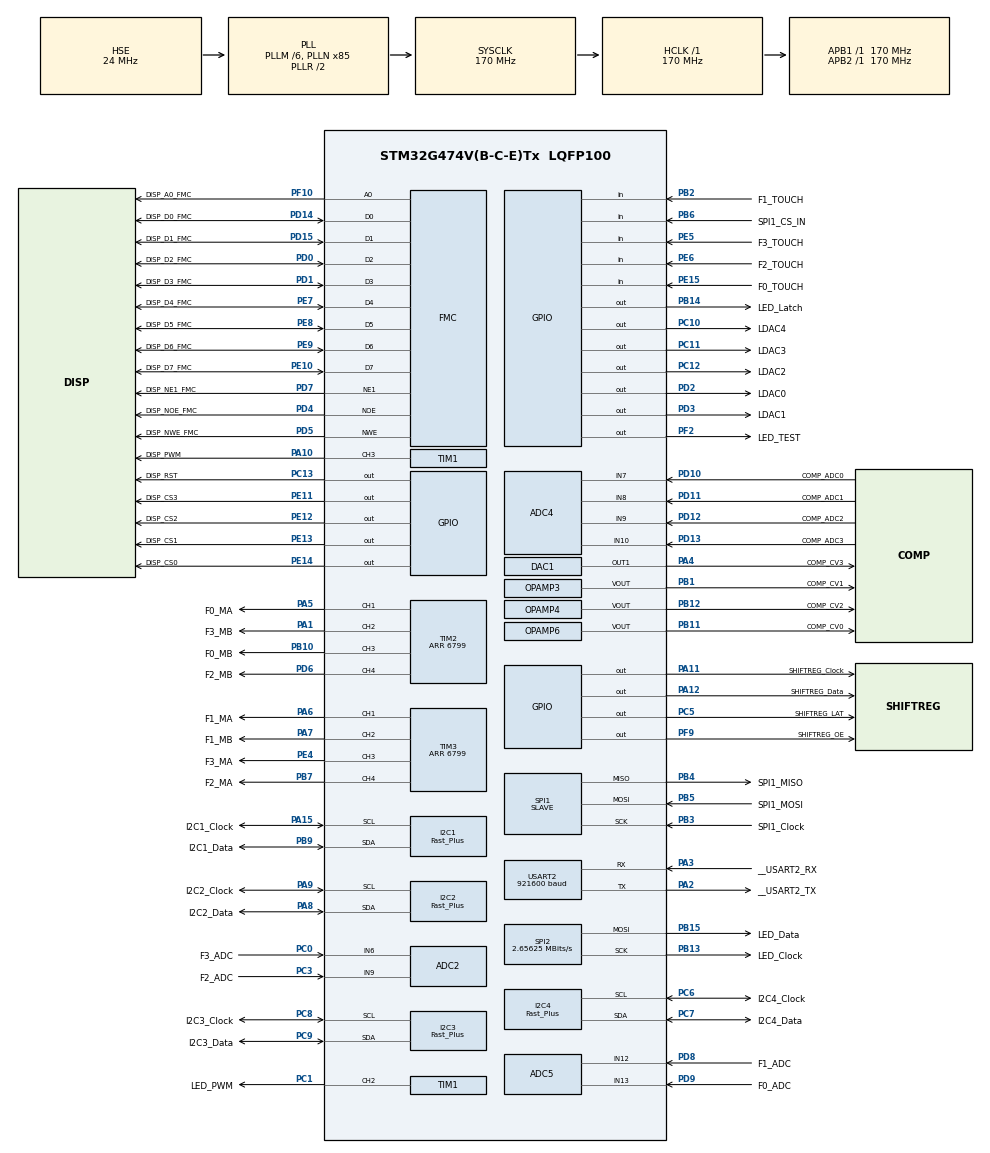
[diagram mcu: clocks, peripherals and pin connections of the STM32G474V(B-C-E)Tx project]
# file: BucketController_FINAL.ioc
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ADC2.Channel-1\#ChannelRegularConversion=ADC_CHANNEL_9
ADC2.Channel-2\#ChannelRegularConversion=ADC_CHANNEL_6
ADC2.ClockPrescaler=ADC_CLOCK_ASYNC_DIV256
ADC2.ContinuousConvMode=ENABLE
ADC2.DMAContinuousRequests=DISABLE
ADC2.NbrOfConversion=2
ADC2.NbrOfConversionFlag=1
ADC2.OffsetNumber-1\#ChannelRegularConversion=ADC_OFFSET_NONE
ADC2.OffsetNumber-2\#ChannelRegularConversion=ADC_OFFSET_NONE
ADC2.Rank-1\#ChannelRegularConversion=1
ADC2.Rank-2\#ChannelRegularConversion=2
ADC2.SamplingTime-1\#ChannelRegularConversion=ADC_SAMPLETIME_2CYCLES_5
ADC2.SamplingTime-2\#ChannelRegularConversion=ADC_SAMPLETIME_2CYCLES_5
ADC4.Channel-1\#ChannelRegularConversion=ADC_CHANNEL_7
ADC4.Channel-2\#ChannelRegularConversion=ADC_CHANNEL_8
ADC4.Channel-3\#ChannelRegularConversion=ADC_CHANNEL_9
ADC4.Channel-4\#ChannelRegularConversion=ADC_CHANNEL_10
ADC4.NbrOfConversion=4
ADC4.NbrOfConversionFlag=1
ADC4.OffsetNumber-1\#ChannelRegularConversion=ADC_OFFSET_NONE
ADC4.OffsetNumber-2\#ChannelRegularConversion=ADC_OFFSET_NONE
ADC4.OffsetNumber-3\#ChannelRegularConversion=ADC_OFFSET_NONE
ADC4.OffsetNumber-4\#ChannelRegularConversion=ADC_OFFSET_NONE
ADC4.Rank-1\#ChannelRegularConversion=1
ADC4.Rank-2\#ChannelRegularConversion=2
ADC4.Rank-3\#ChannelRegularConversion=3
ADC4.Rank-4\#ChannelRegularConversion=4
ADC4.SamplingTime-1\#ChannelRegularConversion=ADC_SAMPLETIME_2CYCLES_5
ADC4.SamplingTime-2\#ChannelRegularConversion=ADC_SAMPLETIME_2CYCLES_5
ADC4.SamplingTime-3\#ChannelRegularConversion=ADC_SAMPLETIME_2CYCLES_5
ADC4.SamplingTime-4\#ChannelRegularConversion=ADC_SAMPLETIME_2CYCLES_5
ADC5.Channel-1\#ChannelRegularConversion=ADC_CHANNEL_13
ADC5.Channel-2\#ChannelRegularConversion=ADC_CHANNEL_12
ADC5.NbrOfConversion=2
ADC5.NbrOfConversionFlag=1
ADC5.OffsetNumber-1\#ChannelRegularConversion=ADC_OFFSET_NONE
ADC5.OffsetNumber-2\#ChannelRegularConversion=ADC_OFFSET_NONE
ADC5.Rank-1\#ChannelRegularConversion=1
ADC5.Rank-2\#ChannelRegularConversion=2
ADC5.SamplingTime-1\#ChannelRegularConversion=ADC_SAMPLETIME_2CYCLES_5
ADC5.SamplingTime-2\#ChannelRegularConversion=ADC_SAMPLETIME_2CYCLES_5
DAC3.DAC_Channel-DAC_OUT2_Int=DAC_CHANNEL_2
Dma.Request0=SPI2_TX
Dma.SPI2_TX.0.Direction=DMA_MEMORY_TO_PERIPH
Dma.SPI2_TX.0.EventEnable=DISABLE
Dma.SPI2_TX.0.Instance=DMA1_Channel1
Dma.SPI2_TX.0.MemDataAlignment=DMA_MDATAALIGN_BYTE
Dma.SPI2_TX.0.MemInc=DMA_MINC_ENABLE
Dma.SPI2_TX.0.Mode=DMA_NORMAL
Dma.SPI2_TX.0.PeriphDataAlignment=DMA_PDATAALIGN_BYTE
Dma.SPI2_TX.0.PeriphInc=DMA_PINC_DISABLE
Dma.SPI2_TX.0.Polarity=HAL_DMAMUX_REQ_GEN_RISING
Dma.SPI2_TX.0.Priority=DMA_PRIORITY_LOW
Dma.SPI2_TX.0.RequestNumber=1
Dma.SPI2_TX.0.SignalID=NONE
Dma.SPI2_TX.0.SyncEnable=DISABLE
Dma.SPI2_TX.0.SyncPolarity=HAL_DMAMUX_SYNC_NO_EVENT
Dma.SPI2_TX.0.SyncRequestNumber=1
Dma.SPI2_TX.0.SyncSignalID=NONE
FMC.AddressSetupTime1=1
FMC.BusTurnAroundDuration1=0
FMC.DataHoldTime1=1
FMC.DataSetupTime1=4
FMC.WriteFifo1=FMC_WRITE_FIFO_DISABLE
FREERTOS.Tasks01=defaultTask,24,128,StartDefaultTask,Default,NULL,Dynamic,NULL,NULL
I2C1.I2C_Speed_Mode=I2C_Fast_Plus
I2C1.Speed=1000
I2C1.Timing=0x4052060F
I2C2.I2C_Speed_Mode=I2C_Fast_Plus
I2C2.Timing=0x4052060F
I2C3.I2C_Speed_Mode=I2C_Fast_Plus
I2C3.Timing=0x4052060F
I2C4.I2C_Speed_Mode=I2C_Fast_Plus
I2C4.Timing=0x4052060F
Mcu.Family=STM32G4
Mcu.Name=STM32G474V(B-C-E)Tx
Mcu.Package=LQFP100
NVIC.DMA1_Channel1_IRQn=true\:5\:0\:false\:false\:true\:true\:false\:true\:true
NVIC.PriorityGroup=NVIC_PRIORITYGROUP_4
NVIC.SPI2_IRQn=true\:5\:0\:false\:false\:true\:true\:true\:true\:true
NVIC.TIM4_IRQn=true\:5\:0\:false\:false\:true\:true\:true\:true\:true
NVIC.TIM5_IRQn=true\:5\:0\:false\:false\:true\:true\:true\:true\:true
NVIC.TIM7_DAC_IRQn=true\:5\:0\:false\:false\:true\:false\:false\:true\:true
NVIC.TimeBase=TIM7_DAC_IRQn
NVIC.TimeBaseIP=TIM7
PA1.GPIO_Label=F3_MB
PA1.GPIO_Speed=GPIO_SPEED_FREQ_HIGH
PA1.Signal=S_TIM2_CH2
PA10.GPIO_Label=DISP_PWM
PA10.Signal=S_TIM1_CH3
PA11.GPIO_Label=SHIFTREG_Clock
PA11.Signal=GPIO_Output
PA12.GPIO_Label=SHIFTREG_Data
PA12.Signal=GPIO_Output
PA13.GPIO_Label=__SWDIO
PA13.Mode=Serial_Wire
PA13.Signal=SYS_JTMS-SWDIO
PA14.GPIO_Label=__SWCLK
PA14.Mode=Serial_Wire
PA14.Signal=SYS_JTCK-SWCLK
PA15.GPIO_Label=I2C1_Clock
PA15.Mode=I2C
PA15.Signal=I2C1_SCL
PA2.GPIO_Label=__USART2_TX
PA2.Mode=Asynchronous
PA2.Signal=USART2_TX
PA3.GPIO_Label=__USART2_RX
PA3.Mode=Asynchronous
PA3.Signal=USART2_RX
PA4.GPIO_Label=COMP_CV3
PA4.Signal=COMP_DAC11_group
PA5.GPIO_Label=F0_MA
PA5.GPIO_Speed=GPIO_SPEED_FREQ_HIGH
PA5.Signal=S_TIM2_CH1
PA6.GPIO_Label=F1_MA
PA6.GPIO_Speed=GPIO_SPEED_FREQ_HIGH
PA6.Signal=S_TIM3_CH1
PA7.GPIO_Label=F1_MB
PA7.GPIO_Speed=GPIO_SPEED_FREQ_HIGH
PA7.Signal=S_TIM3_CH2
PA8.GPIO_Label=I2C2_Data
PA8.Mode=I2C
PA8.Signal=I2C2_SDA
PA9.GPIO_Label=I2C2_Clock
PA9.Mode=I2C
PA9.Signal=I2C2_SCL
PB1.GPIO_Label=COMP_CV1
PB1.Mode=Follower-DAC_OUT2-INP
PB1.Signal=OPAMP3_VOUT
PB10.GPIO_Label=F0_MB
PB10.GPIO_Speed=GPIO_SPEED_FREQ_HIGH
PB10.Signal=S_TIM2_CH3
PB11.GPIO_Label=COMP_CV0
PB11.Mode=Follower-DAC_OUT2-INP
PB11.Signal=OPAMP6_VOUT
PB12.GPIO_Label=COMP_CV2
PB12.Mode=Follower-DAC_OUT2-INP
PB12.Signal=OPAMP4_VOUT
PB13.GPIO_Label=LED_Clock
PB13.GPIO_Speed=GPIO_SPEED_FREQ_LOW
PB13.Mode=TX_Only_Simplex_Unidirect_Master
PB13.Signal=SPI2_SCK
PB14.GPIO_Label=LED_Latch
PB14.Signal=GPIO_Output
PB15.GPIO_Label=LED_Data
PB15.GPIO_Speed=GPIO_SPEED_FREQ_LOW
PB15.Mode=TX_Only_Simplex_Unidirect_Master
PB15.Signal=SPI2_MOSI
PB2.GPIO_Label=F1_TOUCH
PB2.Signal=GPIO_Input
PB3.GPIO_Label=SPI1_Clock
PB3.Mode=Full_Duplex_Slave
PB3.Signal=SPI1_SCK
PB4.GPIO_Label=SPI1_MISO
PB4.Mode=Full_Duplex_Slave
PB4.Signal=SPI1_MISO
PB5.GPIO_Label=SPI1_MOSI
PB5.Mode=Full_Duplex_Slave
PB5.Signal=SPI1_MOSI
PB6.GPIO_Label=SPI1_CS_IN
PB6.Signal=GPIO_Input
PB7.GPIO_Label=F2_MA
PB7.GPIO_Speed=GPIO_SPEED_FREQ_HIGH
PB7.Signal=S_TIM3_CH4
PB9.GPIO_Label=I2C1_Data
PB9.Mode=I2C
PB9.Signal=I2C1_SDA
PC0.GPIO_Label=F3_ADC
PC0.Mode=IN6-Single-Ended
PC0.Signal=ADC2_IN6
PC1.GPIO_Label=LED_PWM
PC1.Signal=S_TIM1_CH2
PC10.GPIO_Label=LDAC4
PC10.Signal=GPIO_Output
PC11.GPIO_Label=LDAC3
PC11.Signal=GPIO_Output
PC12.GPIO_Label=LDAC2
PC12.Signal=GPIO_Output
PC13.GPIO_Label=DISP_RST
PC13.Signal=GPIO_Output
PC3.GPIO_Label=F2_ADC
PC3.Mode=IN9-Single-Ended
PC3.Signal=ADC2_IN9
PC5.GPIO_Label=SHIFTREG_LAT
PC5.Signal=GPIO_Output
PC6.GPIO_Label=I2C4_Clock
PC6.Mode=I2C
PC6.Signal=I2C4_SCL
PC7.GPIO_Label=I2C4_Data
PC7.Mode=I2C
PC7.Signal=I2C4_SDA
PC8.GPIO_Label=I2C3_Clock
PC8.Mode=I2C
PC8.Signal=I2C3_SCL
PC9.GPIO_Label=I2C3_Data
PC9.Mode=I2C
PC9.Signal=I2C3_SDA
PD0.GPIO_Label=DISP_D2_FMC
PD0.Mode=8b-d1
PD0.Signal=FMC_D2
PD1.GPIO_Label=DISP_D3_FMC
PD1.Mode=8b-d1
PD1.Signal=FMC_D3
PD10.GPIO_Label=COMP_ADC0
PD10.Mode=IN7-Single-Ended
PD10.Signal=ADC4_IN7
PD11.GPIO_Label=COMP_ADC1
PD11.Mode=IN8-Single-Ended
PD11.Signal=ADC4_IN8
PD12.GPIO_Label=COMP_ADC2
PD12.Mode=IN9-Single-Ended
PD12.Signal=ADC4_IN9
PD13.GPIO_Label=COMP_ADC3
PD13.Mode=IN10-Single-Ended
PD13.Signal=ADC4_IN10
PD14.GPIO_Label=DISP_D0_FMC
PD14.Mode=8b-d1
PD14.Signal=FMC_D0
PD15.GPIO_Label=DISP_D1_FMC
PD15.Mode=8b-d1
PD15.Signal=FMC_D1
PD2.GPIO_Label=LDAC0
PD2.Signal=GPIO_Output
PD3.GPIO_Label=LDAC1
PD3.Signal=GPIO_Output
PD4.GPIO_Label=DISP_NOE_FMC
PD4.Mode=Lcd1
PD4.Signal=FMC_NOE
PD5.GPIO_Label=DISP_NWE_FMC
PD5.Mode=Lcd1
PD5.Signal=FMC_NWE
PD6.GPIO_Label=F2_MB
PD6.GPIO_Speed=GPIO_SPEED_FREQ_HIGH
PD6.Signal=S_TIM2_CH4
PD7.GPIO_Label=DISP_NE1_FMC
PD7.Mode=NorPsramChipSelect1_1
PD7.Signal=FMC_NE1
PD8.GPIO_Label=F1_ADC
PD8.Mode=IN12-Single-Ended
PD8.Signal=ADC5_IN12
PD9.GPIO_Label=F0_ADC
PD9.Mode=IN13-Single-Ended
PD9.Signal=ADC5_IN13
PE10.GPIO_Label=DISP_D7_FMC
PE10.Mode=8b-d1
PE10.Signal=FMC_D7
PE11.GPIO_Label=DISP_CS3
PE11.Signal=GPIO_Output
PE12.GPIO_Label=DISP_CS2
PE12.Signal=GPIO_Output
PE13.GPIO_Label=DISP_CS1
PE13.Signal=GPIO_Output
PE14.GPIO_Label=DISP_CS0
PE14.Signal=GPIO_Output
PE15.GPIO_Label=F0_TOUCH
PE15.Signal=GPIO_Input
PE4.GPIO_Label=F3_MA
PE4.GPIO_Speed=GPIO_SPEED_FREQ_HIGH
PE4.Signal=S_TIM3_CH3
PE5.GPIO_Label=F3_TOUCH
PE5.Signal=GPIO_Input
PE6.GPIO_Label=F2_TOUCH
PE6.Signal=GPIO_Input
PE7.GPIO_Label=DISP_D4_FMC
PE7.Mode=8b-d1
PE7.Signal=FMC_D4
PE8.GPIO_Label=DISP_D5_FMC
PE8.Mode=8b-d1
PE8.Signal=FMC_D5
PE9.GPIO_Label=DISP_D6_FMC
PE9.Mode=8b-d1
PE9.Signal=FMC_D6
PF0-OSC_IN.GPIO_Label=__OSC_IN
PF0-OSC_IN.Mode=HSE-External-Oscillator
PF0-OSC_IN.Signal=RCC_OSC_IN
PF1-OSC_OUT.GPIO_Label=__OSC_OUT
PF1-OSC_OUT.Mode=HSE-External-Oscillator
PF1-OSC_OUT.Signal=RCC_OSC_OUT
PF10.GPIO_Label=DISP_A0_FMC
PF10.Mode=A0_1
PF10.Signal=FMC_A0
PF2.GPIO_Label=LED_TEST
PF2.Signal=GPIO_Output
PF9.GPIO_Label=SHIFTREG_OE
PF9.PinState=GPIO_PIN_SET
PF9.Signal=GPIO_Output
ProjectManager.HeapSize=0x200
ProjectManager.StackSize=0x400
ProjectManager.TargetToolchain=CMake
RCC.ADC12Freq_Value=170000000
RCC.ADC345Freq_Value=170000000
RCC.AHBFreq_Value=170000000
RCC.APB1Freq_Value=170000000
RCC.APB1TimFreq_Value=170000000
RCC.APB2Freq_Value=170000000
RCC.APB2TimFreq_Value=170000000
RCC.CK48CLockSelection=RCC_USBCLKSOURCE_HSI48
RCC.CortexFreq_Value=170000000
RCC.EXTERNAL_CLOCK_VALUE=12288000
RCC.HCLKFreq_Value=170000000
RCC.HSE_VALUE=24000000
RCC.HSI48_VALUE=48000000
RCC.HSI_VALUE=16000000
RCC.LSE_VALUE=32768
RCC.PLLM=RCC_PLLM_DIV6
RCC.PLLN=85
RCC.PLLP=RCC_PLLP_DIV6
RCC.PLLQ=RCC_PLLQ_DIV4
RCC.PLLSourceVirtual=RCC_PLLSOURCE_HSE
RCC.SYSCLKFreq_VALUE=170000000
RCC.SYSCLKSource=RCC_SYSCLKSOURCE_PLLCLK
RCC.USBFreq_Value=48000000
RCC.VCOOutputFreq_Value=340000000
SH.COMP_DAC11_group.0=DAC1_OUT1,DAC_OUT1
SH.S_TIM1_CH2.0=TIM1_CH2,PWM Generation2 CH2
SH.S_TIM1_CH3.0=TIM1_CH3,PWM Generation3 CH3
SH.S_TIM2_CH1.0=TIM2_CH1,PWM Generation1 CH1
SH.S_TIM2_CH2.0=TIM2_CH2,PWM Generation2 CH2
SH.S_TIM2_CH3.0=TIM2_CH3,PWM Generation3 CH3
SH.S_TIM2_CH4.0=TIM2_CH4,PWM Generation4 CH4
SH.S_TIM3_CH1.0=TIM3_CH1,PWM Generation1 CH1
SH.S_TIM3_CH2.0=TIM3_CH2,PWM Generation2 CH2
SH.S_TIM3_CH3.0=TIM3_CH3,PWM Generation3 CH3
SH.S_TIM3_CH4.0=TIM3_CH4,PWM Generation4 CH4
SPI1.Direction=SPI_DIRECTION_2LINES
SPI1.Mode=SPI_MODE_SLAVE
SPI1.VirtualType=VM_SLAVE
SPI2.BaudRatePrescaler=SPI_BAUDRATEPRESCALER_64
SPI2.CLKPhase=SPI_PHASE_2EDGE
SPI2.CLKPolarity=SPI_POLARITY_LOW
SPI2.CalculateBaudRate=2.65625 MBits/s
SPI2.DataSize=SPI_DATASIZE_8BIT
SPI2.Direction=SPI_DIRECTION_2LINES
SPI2.Mode=SPI_MODE_MASTER
SPI2.VirtualType=VM_MASTER
TIM1.Channel-PWM\ Generation2\ CH2=TIM_CHANNEL_2
TIM1.Channel-PWM\ Generation3\ CH3=TIM_CHANNEL_3
TIM1.PeriodNoDither=6799
TIM2.Channel-PWM\ Generation1\ CH1=TIM_CHANNEL_1
TIM2.Channel-PWM\ Generation2\ CH2=TIM_CHANNEL_2
TIM2.Channel-PWM\ Generation3\ CH3=TIM_CHANNEL_3
TIM2.Channel-PWM\ Generation4\ CH4=TIM_CHANNEL_4
TIM2.OCPolarity_1=TIM_OCPOLARITY_HIGH
TIM2.OCPolarity_2=TIM_OCPOLARITY_HIGH
TIM2.PeriodNoDither=6799
TIM3.Channel-PWM\ Generation1\ CH1=TIM_CHANNEL_1
TIM3.Channel-PWM\ Generation2\ CH2=TIM_CHANNEL_2
TIM3.Channel-PWM\ Generation3\ CH3=TIM_CHANNEL_3
TIM3.Channel-PWM\ Generation4\ CH4=TIM_CHANNEL_4
TIM3.PeriodNoDither=6799
TIM4.PeriodNoDither=666
TIM4.Prescaler=169
TIM5.PeriodNoDither=8332
TIM5.Prescaler=169
USART2.BaudRate=921600
USART2.VirtualMode-Asynchronous=VM_ASYNC
VP_DAC3_VS_DACI1.Mode=DAC_OUT1_Int
VP_DAC3_VS_DACI2.Mode=DAC_OUT2_Int
VP_DAC4_VS_DACI1.Mode=DAC_OUT1_Int
VP_FREERTOS_VS_CMSIS_V2.Mode=CMSIS_V2
VP_SYS_VS_DBSignals.Mode=DisableDeadBatterySignals
VP_SYS_VS_tim7.Mode=TIM7
VP_TIM2_VS_ClockSourceINT.Mode=Internal
VP_TIM3_VS_ClockSourceINT.Mode=Internal
VP_TIM4_VS_ClockSourceINT.Mode=Internal
VP_TIM5_VS_ClockSourceINT.Mode=Internal
board=custom

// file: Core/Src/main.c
/* USER CODE BEGIN Header */
/**
  ******************************************************************************
  * @file           : main.c
  * @brief          : Main program body
  ******************************************************************************
  * @attention
  *
  * Copyright (c) 2026 STMicroelectronics.
  * All rights reserved.
  *
  * This software is licensed under terms that can be found in the LICENSE file
  * in the root directory of this software component.
  * If no LICENSE file comes with this software, it is provided AS-IS.
  *
  ******************************************************************************
  */
/* USER CODE END Header */
#include "main.h"
#include "cmsis_os.h"

/* USER CODE BEGIN Includes */

#include <stdio.h>

// Skylar
#include "CONFIG.h"
#include "cmsis_os2.h"
#include "control_integration/control_interface.h"
#include "hardware_drivers/fader_driver.h"
#include "hardware_drivers/i2c_driver.h"
#include "hardware_drivers/mcp23017.h"
#include "hardware_drivers/mcp4728.h"
#include "hardware_drivers/mcp4728_cache.h"
#include "hardware_drivers/rotary_encoder.h"
#include "hardware_drivers/led_driver.h"
#include "hardware_drivers/74hc595.h"
#include "portmacro.h"
#include "projdefs.h"
#include "stm32g474xx.h"
#include "FreeRTOS_apps/master_link.h"
#include "FreeRTOS_apps/boot_screen.h"
#include "FreeRTOS_apps/led_handler.h"
#include "FreeRTOS_apps/i2c_scheduler.h"
#include "FreeRTOS_apps/fader_poller.h"
#include "FreeRTOS_apps/displays.h"
#include "FreeRTOS_apps/channel_display.h"
#include "stm32g4xx_hal.h"

/* USER CODE END Includes */

ADC_HandleTypeDef hadc2;
ADC_HandleTypeDef hadc4;
ADC_HandleTypeDef hadc5;

DAC_HandleTypeDef hdac1;
DAC_HandleTypeDef hdac3;
DAC_HandleTypeDef hdac4;

I2C_HandleTypeDef hi2c1;
I2C_HandleTypeDef hi2c2;
I2C_HandleTypeDef hi2c3;
I2C_HandleTypeDef hi2c4;

OPAMP_HandleTypeDef hopamp3;
OPAMP_HandleTypeDef hopamp4;
OPAMP_HandleTypeDef hopamp6;

SPI_HandleTypeDef hspi1;
SPI_HandleTypeDef hspi2;
DMA_HandleTypeDef hdma_spi2_tx;

TIM_HandleTypeDef htim1;
TIM_HandleTypeDef htim2;
TIM_HandleTypeDef htim3;
TIM_HandleTypeDef htim4;
TIM_HandleTypeDef htim5;

UART_HandleTypeDef huart2;

SRAM_HandleTypeDef hsram1;

/* Definitions for defaultTask */
osThreadId_t defaultTaskHandle;
const osThreadAttr_t defaultTask_attributes = {
  .name = "defaultTask",
  .priority = (osPriority_t) osPriorityNormal,
  .stack_size = 128 * 4
};

void SystemClock_Config(void);
static void MX_GPIO_Init(void);
static void MX_DMA_Init(void);
static void MX_ADC2_Init(void);
static void MX_DAC3_Init(void);
static void MX_I2C1_Init(void);
static void MX_I2C2_Init(void);
static void MX_I2C3_Init(void);
static void MX_I2C4_Init(void);
static void MX_SPI1_Init(void);
static void MX_SPI2_Init(void);
static void MX_TIM1_Init(void);
static void MX_TIM2_Init(void);
static void MX_TIM3_Init(void);
static void MX_TIM4_Init(void);
static void MX_TIM5_Init(void);
static void MX_USART2_UART_Init(void);
static void MX_DAC4_Init(void);
static void MX_FMC_Init(void);
static void MX_OPAMP3_Init(void);
static void MX_OPAMP4_Init(void);
static void MX_OPAMP6_Init(void);
static void MX_ADC4_Init(void);
static void MX_DAC1_Init(void);
static void MX_ADC5_Init(void);
void StartDefaultTask(void *argument);

/* USER CODE BEGIN 0 */

// start usart2 usb debug
// picocom -b 115200 /dev/cu.usbmodem#####
int __io_putchar(int ch)
{
  if (DEVELOPER_MODE)
  {
    HAL_UART_Transmit(&REMOTE_UART_HANDLE, (uint8_t *)&ch, 1, 100);
  }
  return ch;
}

/* USER CODE END 0 */

int main(void)
{

  /* MCU Configuration--------------------------------------------------------*/

  /* Reset of all peripherals, Initializes the Flash interface and the Systick. */
  HAL_Init();

  /* Configure the system clock */
  SystemClock_Config();

  /* Initialize all configured peripherals */
  MX_GPIO_Init();
  MX_DMA_Init();
  MX_ADC2_Init();
  MX_DAC3_Init();
  MX_I2C1_Init();
  MX_I2C2_Init();
  MX_I2C3_Init();
  MX_I2C4_Init();
  MX_SPI1_Init();
  MX_SPI2_Init();
  MX_TIM1_Init();
  MX_TIM2_Init();
  MX_TIM3_Init();
  MX_TIM4_Init();
  MX_TIM5_Init();
  MX_USART2_UART_Init();
  MX_DAC4_Init();
  MX_FMC_Init();
  MX_OPAMP3_Init();
  MX_OPAMP4_Init();
  MX_OPAMP6_Init();
  MX_ADC4_Init();
  MX_DAC1_Init();
  MX_ADC5_Init();
  /* USER CODE BEGIN 2 */

  /*=============================== STARTUP HARDWARE INITIALIZATION ================================*/

  if(DEVELOPER_MODE)
  {
    setvbuf(stdout, NULL, _IONBF, 0); // make lines never disappear on the remote UART
  }

  i2c_init(); // i2c startup

  if(DEVELOPER_MODE)
  {
    printf("\r\n\n\n\n\n\n\n\n\n*******************************************************\r\n");
    printf("Initializing Bucket Controller...\r\n    Build %s %s \r\n\nBEGIN debug log:\r\n", __DATE__, __TIME__);
    printf("*******************************************************\r\n");

    i2c_probeall();
  }

  // SPI1 slave to the master (our channel numbers, remote commands in, panel changes out). Early, so PB4
  // stops driving the MISO line the four buckets share; its task starts with the scheduler.
  master_link_init();

  led_init(); // PLEASE keep led_init before init_control_interface. otherwise control hardware gets set to nullptrs and we have no LEDs
  shiftreg_init();

  led_brightness(10);

  // I2C DEVICES INIT
  const uint8_t mcp23017s_per_channel = sizeof(MCP23017_ADDRS) / sizeof(MCP23017_ADDRS[0]);
  const uint8_t mcp4728s_per_channel = sizeof(MCP4728_ADDRS) / sizeof(MCP4728_ADDRS[0]);

  mcp4728_init_all_addresses();

  for(uint8_t ch = 0; ch < CHANNELS; ch++){
    for(uint8_t mcp23017_idx = 0; mcp23017_idx < mcp23017s_per_channel; mcp23017_idx++){
      mcp23017_init(i2c_channel_bus(ch), MCP23017_ADDRS[mcp23017_idx]);
    }
    for(uint8_t mcp4728_idx = 0; mcp4728_idx < mcp4728s_per_channel; mcp4728_idx++){
      mcp4728_init_settings(i2c_channel_bus(ch), MCP4728_ADDRS[mcp4728_idx]);
    }
  }
  init_control_interface();

  if(DEVELOPER_MODE)
  {
  led_print_config();

  printf("\r\n*******************************************************\n");
  }

  displays_init();

  /*=============================== END STARTUP HARDWARE INITIALIZATION ================================*/

  /* USER CODE END 2 */

  /* Init scheduler */
  osKernelInitialize();

  /* Create the thread(s) */
  /* creation of defaultTask */
  defaultTaskHandle = osThreadNew(StartDefaultTask, NULL, &defaultTask_attributes);

  /* USER CODE BEGIN RTOS_THREADS */

  init_led_handler(); // start LED frame renderer
  init_i2c_scheduler();
  init_fader_poller();
  init_faders();
  boot_screen_init();     // start-up picture and LED animation until the master answers (or solo mode)
  init_channel_display(); // channel screens (after displays_init and init_control_interface)

  /* USER CODE END RTOS_THREADS */

  /* Start scheduler */
  osKernelStart();

  /* We should never get here as control is now taken by the scheduler */

  /* Infinite loop */
  while (1)
  {

  }
}

void SystemClock_Config(void)
{
  RCC_OscInitTypeDef RCC_OscInitStruct = {0};
  RCC_ClkInitTypeDef RCC_ClkInitStruct = {0};

  /** Configure the main internal regulator output voltage
  */
  HAL_PWREx_ControlVoltageScaling(PWR_REGULATOR_VOLTAGE_SCALE1_BOOST);

  /** Initializes the RCC Oscillators according to the specified parameters
  * in the RCC_OscInitTypeDef structure.
  */
  RCC_OscInitStruct.OscillatorType = RCC_OSCILLATORTYPE_HSE;
  RCC_OscInitStruct.HSEState = RCC_HSE_ON;
  RCC_OscInitStruct.PLL.PLLState = RCC_PLL_ON;
  RCC_OscInitStruct.PLL.PLLSource = RCC_PLLSOURCE_HSE;
  RCC_OscInitStruct.PLL.PLLM = RCC_PLLM_DIV6;
  RCC_OscInitStruct.PLL.PLLN = 85;
  RCC_OscInitStruct.PLL.PLLP = RCC_PLLP_DIV6;
  RCC_OscInitStruct.PLL.PLLQ = RCC_PLLQ_DIV4;
  RCC_OscInitStruct.PLL.PLLR = RCC_PLLR_DIV2;
  if (HAL_RCC_OscConfig(&RCC_OscInitStruct) != HAL_OK)
  {
    Error_Handler();
  }

  /** Initializes the CPU, AHB and APB buses clocks
  */
  RCC_ClkInitStruct.ClockType = RCC_CLOCKTYPE_HCLK|RCC_CLOCKTYPE_SYSCLK
                              |RCC_CLOCKTYPE_PCLK1|RCC_CLOCKTYPE_PCLK2;
  RCC_ClkInitStruct.SYSCLKSource = RCC_SYSCLKSOURCE_PLLCLK;
  RCC_ClkInitStruct.AHBCLKDivider = RCC_SYSCLK_DIV1;
  RCC_ClkInitStruct.APB1CLKDivider = RCC_HCLK_DIV1;
  RCC_ClkInitStruct.APB2CLKDivider = RCC_HCLK_DIV1;

  if (HAL_RCC_ClockConfig(&RCC_ClkInitStruct, FLASH_LATENCY_4) != HAL_OK)
  {
    Error_Handler();
  }
}

static void MX_ADC2_Init(void)
{

  ADC_ChannelConfTypeDef sConfig = {0};

  /** Common config
  */
  hadc2.Instance = ADC2;
  hadc2.Init.ClockPrescaler = ADC_CLOCK_ASYNC_DIV256;
  hadc2.Init.Resolution = ADC_RESOLUTION_12B;
  hadc2.Init.DataAlign = ADC_DATAALIGN_RIGHT;
  hadc2.Init.GainCompensation = 0;
  hadc2.Init.ScanConvMode = ADC_SCAN_ENABLE;
  hadc2.Init.EOCSelection = ADC_EOC_SINGLE_CONV;
  hadc2.Init.LowPowerAutoWait = DISABLE;
  hadc2.Init.ContinuousConvMode = ENABLE;
  hadc2.Init.NbrOfConversion = 2;
  hadc2.Init.DiscontinuousConvMode = DISABLE;
  hadc2.Init.ExternalTrigConv = ADC_SOFTWARE_START;
  hadc2.Init.ExternalTrigConvEdge = ADC_EXTERNALTRIGCONVEDGE_NONE;
  hadc2.Init.DMAContinuousRequests = DISABLE;
  hadc2.Init.Overrun = ADC_OVR_DATA_PRESERVED;
  hadc2.Init.OversamplingMode = DISABLE;
  if (HAL_ADC_Init(&hadc2) != HAL_OK)
  {
    Error_Handler();
  }

  /** Configure Regular Channel
  */
  sConfig.Channel = ADC_CHANNEL_9;
  sConfig.Rank = ADC_REGULAR_RANK_1;
  sConfig.SamplingTime = ADC_SAMPLETIME_2CYCLES_5;
  sConfig.SingleDiff = ADC_SINGLE_ENDED;
  sConfig.OffsetNumber = ADC_OFFSET_NONE;
  sConfig.Offset = 0;
  if (HAL_ADC_ConfigChannel(&hadc2, &sConfig) != HAL_OK)
  {
    Error_Handler();
  }

  /** Configure Regular Channel
  */
  sConfig.Channel = ADC_CHANNEL_6;
  sConfig.Rank = ADC_REGULAR_RANK_2;
  if (HAL_ADC_ConfigChannel(&hadc2, &sConfig) != HAL_OK)
  {
    Error_Handler();
  }

}

static void MX_ADC4_Init(void)
{

  ADC_ChannelConfTypeDef sConfig = {0};

  /** Common config
  */
  hadc4.Instance = ADC4;
  hadc4.Init.ClockPrescaler = ADC_CLOCK_SYNC_PCLK_DIV4;
  hadc4.Init.Resolution = ADC_RESOLUTION_12B;
  hadc4.Init.DataAlign = ADC_DATAALIGN_RIGHT;
  hadc4.Init.GainCompensation = 0;
  hadc4.Init.ScanConvMode = ADC_SCAN_ENABLE;
  hadc4.Init.EOCSelection = ADC_EOC_SINGLE_CONV;
  hadc4.Init.LowPowerAutoWait = DISABLE;
  hadc4.Init.ContinuousConvMode = DISABLE;
  hadc4.Init.NbrOfConversion = 4;
  hadc4.Init.DiscontinuousConvMode = DISABLE;
  hadc4.Init.ExternalTrigConv = ADC_SOFTWARE_START;
  hadc4.Init.ExternalTrigConvEdge = ADC_EXTERNALTRIGCONVEDGE_NONE;
  hadc4.Init.DMAContinuousRequests = DISABLE;
  hadc4.Init.Overrun = ADC_OVR_DATA_PRESERVED;
  hadc4.Init.OversamplingMode = DISABLE;
  if (HAL_ADC_Init(&hadc4) != HAL_OK)
  {
    Error_Handler();
  }

  /** Configure Regular Channel
  */
  sConfig.Channel = ADC_CHANNEL_7;
  sConfig.Rank = ADC_REGULAR_RANK_1;
  sConfig.SamplingTime = ADC_SAMPLETIME_2CYCLES_5;
  sConfig.SingleDiff = ADC_SINGLE_ENDED;
  sConfig.OffsetNumber = ADC_OFFSET_NONE;
  sConfig.Offset = 0;
  if (HAL_ADC_ConfigChannel(&hadc4, &sConfig) != HAL_OK)
  {
    Error_Handler();
  }

  /** Configure Regular Channel
  */
  sConfig.Channel = ADC_CHANNEL_8;
  sConfig.Rank = ADC_REGULAR_RANK_2;
  if (HAL_ADC_ConfigChannel(&hadc4, &sConfig) != HAL_OK)
  {
    Error_Handler();
  }

  /** Configure Regular Channel
  */
  sConfig.Channel = ADC_CHANNEL_9;
  sConfig.Rank = ADC_REGULAR_RANK_3;
  if (HAL_ADC_ConfigChannel(&hadc4, &sConfig) != HAL_OK)
  {
    Error_Handler();
  }

  /** Configure Regular Channel
  */
  sConfig.Channel = ADC_CHANNEL_10;
  sConfig.Rank = ADC_REGULAR_RANK_4;
  if (HAL_ADC_ConfigChannel(&hadc4, &sConfig) != HAL_OK)
  {
    Error_Handler();
  }

}

static void MX_ADC5_Init(void)
{

  ADC_ChannelConfTypeDef sConfig = {0};

  /** Common config
  */
  hadc5.Instance = ADC5;
  hadc5.Init.ClockPrescaler = ADC_CLOCK_SYNC_PCLK_DIV4;
  hadc5.Init.Resolution = ADC_RESOLUTION_12B;
  hadc5.Init.DataAlign = ADC_DATAALIGN_RIGHT;
  hadc5.Init.GainCompensation = 0;
  hadc5.Init.ScanConvMode = ADC_SCAN_ENABLE;
  hadc5.Init.EOCSelection = ADC_EOC_SINGLE_CONV;
  hadc5.Init.LowPowerAutoWait = DISABLE;
  hadc5.Init.ContinuousConvMode = DISABLE;
  hadc5.Init.NbrOfConversion = 2;
  hadc5.Init.DiscontinuousConvMode = DISABLE;
  hadc5.Init.ExternalTrigConv = ADC_SOFTWARE_START;
  hadc5.Init.ExternalTrigConvEdge = ADC_EXTERNALTRIGCONVEDGE_NONE;
  hadc5.Init.DMAContinuousRequests = DISABLE;
  hadc5.Init.Overrun = ADC_OVR_DATA_PRESERVED;
  hadc5.Init.OversamplingMode = DISABLE;
  if (HAL_ADC_Init(&hadc5) != HAL_OK)
  {
    Error_Handler();
  }

  /** Configure Regular Channel
  */
  sConfig.Channel = ADC_CHANNEL_13;
  sConfig.Rank = ADC_REGULAR_RANK_1;
  sConfig.SamplingTime = ADC_SAMPLETIME_2CYCLES_5;
  sConfig.SingleDiff = ADC_SINGLE_ENDED;
  sConfig.OffsetNumber = ADC_OFFSET_NONE;
  sConfig.Offset = 0;
  if (HAL_ADC_ConfigChannel(&hadc5, &sConfig) != HAL_OK)
  {
    Error_Handler();
  }

  /** Configure Regular Channel
  */
  sConfig.Channel = ADC_CHANNEL_12;
  sConfig.Rank = ADC_REGULAR_RANK_2;
  if (HAL_ADC_ConfigChannel(&hadc5, &sConfig) != HAL_OK)
  {
    Error_Handler();
  }

}

static void MX_DAC1_Init(void)
{

  DAC_ChannelConfTypeDef sConfig = {0};

  /** DAC Initialization
  */
  hdac1.Instance = DAC1;
  if (HAL_DAC_Init(&hdac1) != HAL_OK)
  {
    Error_Handler();
  }

  /** DAC channel OUT1 config
  */
  sConfig.DAC_HighFrequency = DAC_HIGH_FREQUENCY_INTERFACE_MODE_AUTOMATIC;
  sConfig.DAC_DMADoubleDataMode = DISABLE;
  sConfig.DAC_SignedFormat = DISABLE;
  sConfig.DAC_SampleAndHold = DAC_SAMPLEANDHOLD_DISABLE;
  sConfig.DAC_Trigger = DAC_TRIGGER_NONE;
  sConfig.DAC_Trigger2 = DAC_TRIGGER_NONE;
  sConfig.DAC_OutputBuffer = DAC_OUTPUTBUFFER_ENABLE;
  sConfig.DAC_ConnectOnChipPeripheral = DAC_CHIPCONNECT_EXTERNAL;
  sConfig.DAC_UserTrimming = DAC_TRIMMING_FACTORY;
  if (HAL_DAC_ConfigChannel(&hdac1, &sConfig, DAC_CHANNEL_1) != HAL_OK)
  {
    Error_Handler();
  }

}

static void MX_DAC3_Init(void)
{

  DAC_ChannelConfTypeDef sConfig = {0};

  /** DAC Initialization
  */
  hdac3.Instance = DAC3;
  if (HAL_DAC_Init(&hdac3) != HAL_OK)
  {
    Error_Handler();
  }

  /** DAC channel OUT1 config
  */
  sConfig.DAC_HighFrequency = DAC_HIGH_FREQUENCY_INTERFACE_MODE_AUTOMATIC;
  sConfig.DAC_DMADoubleDataMode = DISABLE;
  sConfig.DAC_SignedFormat = DISABLE;
  sConfig.DAC_SampleAndHold = DAC_SAMPLEANDHOLD_DISABLE;
  sConfig.DAC_Trigger = DAC_TRIGGER_NONE;
  sConfig.DAC_Trigger2 = DAC_TRIGGER_NONE;
  sConfig.DAC_OutputBuffer = DAC_OUTPUTBUFFER_DISABLE;
  sConfig.DAC_ConnectOnChipPeripheral = DAC_CHIPCONNECT_INTERNAL;
  sConfig.DAC_UserTrimming = DAC_TRIMMING_FACTORY;
  if (HAL_DAC_ConfigChannel(&hdac3, &sConfig, DAC_CHANNEL_1) != HAL_OK)
  {
    Error_Handler();
  }

  /** DAC channel OUT2 config
  */
  if (HAL_DAC_ConfigChannel(&hdac3, &sConfig, DAC_CHANNEL_2) != HAL_OK)
  {
    Error_Handler();
  }

}

static void MX_DAC4_Init(void)
{

  DAC_ChannelConfTypeDef sConfig = {0};

  /** DAC Initialization
  */
  hdac4.Instance = DAC4;
  if (HAL_DAC_Init(&hdac4) != HAL_OK)
  {
    Error_Handler();
  }

  /** DAC channel OUT1 config
  */
  sConfig.DAC_HighFrequency = DAC_HIGH_FREQUENCY_INTERFACE_MODE_AUTOMATIC;
  sConfig.DAC_DMADoubleDataMode = DISABLE;
  sConfig.DAC_SignedFormat = DISABLE;
  sConfig.DAC_SampleAndHold = DAC_SAMPLEANDHOLD_DISABLE;
  sConfig.DAC_Trigger = DAC_TRIGGER_NONE;
  sConfig.DAC_Trigger2 = DAC_TRIGGER_NONE;
  sConfig.DAC_OutputBuffer = DAC_OUTPUTBUFFER_DISABLE;
  sConfig.DAC_ConnectOnChipPeripheral = DAC_CHIPCONNECT_INTERNAL;
  sConfig.DAC_UserTrimming = DAC_TRIMMING_FACTORY;
  if (HAL_DAC_ConfigChannel(&hdac4, &sConfig, DAC_CHANNEL_1) != HAL_OK)
  {
    Error_Handler();
  }

}

static void MX_I2C1_Init(void)
{

  hi2c1.Instance = I2C1;
  hi2c1.Init.Timing = 0x4052060F;
  hi2c1.Init.OwnAddress1 = 0;
  hi2c1.Init.AddressingMode = I2C_ADDRESSINGMODE_7BIT;
  hi2c1.Init.DualAddressMode = I2C_DUALADDRESS_DISABLE;
  hi2c1.Init.OwnAddress2 = 0;
  hi2c1.Init.OwnAddress2Masks = I2C_OA2_NOMASK;
  hi2c1.Init.GeneralCallMode = I2C_GENERALCALL_DISABLE;
  hi2c1.Init.NoStretchMode = I2C_NOSTRETCH_DISABLE;
  if (HAL_I2C_Init(&hi2c1) != HAL_OK)
  {
    Error_Handler();
  }

  /** Configure Analogue filter
  */
  if (HAL_I2CEx_ConfigAnalogFilter(&hi2c1, I2C_ANALOGFILTER_ENABLE) != HAL_OK)
  {
    Error_Handler();
  }

  /** Configure Digital filter
  */
  if (HAL_I2CEx_ConfigDigitalFilter(&hi2c1, 0) != HAL_OK)
  {
    Error_Handler();
  }

  /** I2C Fast mode Plus enable
  */
  HAL_I2CEx_EnableFastModePlus(I2C_FASTMODEPLUS_I2C1);

}

static void MX_I2C2_Init(void)
{

  hi2c2.Instance = I2C2;
  hi2c2.Init.Timing = 0x4052060F;
  hi2c2.Init.OwnAddress1 = 0;
  hi2c2.Init.AddressingMode = I2C_ADDRESSINGMODE_7BIT;
  hi2c2.Init.DualAddressMode = I2C_DUALADDRESS_DISABLE;
  hi2c2.Init.OwnAddress2 = 0;
  hi2c2.Init.OwnAddress2Masks = I2C_OA2_NOMASK;
  hi2c2.Init.GeneralCallMode = I2C_GENERALCALL_DISABLE;
  hi2c2.Init.NoStretchMode = I2C_NOSTRETCH_DISABLE;
  if (HAL_I2C_Init(&hi2c2) != HAL_OK)
  {
    Error_Handler();
  }

  /** Configure Analogue filter
  */
  if (HAL_I2CEx_ConfigAnalogFilter(&hi2c2, I2C_ANALOGFILTER_ENABLE) != HAL_OK)
  {
    Error_Handler();
  }

  /** Configure Digital filter
  */
  if (HAL_I2CEx_ConfigDigitalFilter(&hi2c2, 0) != HAL_OK)
  {
    Error_Handler();
  }

  /** I2C Fast mode Plus enable
  */
  HAL_I2CEx_EnableFastModePlus(I2C_FASTMODEPLUS_I2C2);

}

static void MX_I2C3_Init(void)
{

  hi2c3.Instance = I2C3;
  hi2c3.Init.Timing = 0x4052060F;
  hi2c3.Init.OwnAddress1 = 0;
  hi2c3.Init.AddressingMode = I2C_ADDRESSINGMODE_7BIT;
  hi2c3.Init.DualAddressMode = I2C_DUALADDRESS_DISABLE;
  hi2c3.Init.OwnAddress2 = 0;
  hi2c3.Init.OwnAddress2Masks = I2C_OA2_NOMASK;
  hi2c3.Init.GeneralCallMode = I2C_GENERALCALL_DISABLE;
  hi2c3.Init.NoStretchMode = I2C_NOSTRETCH_DISABLE;
  if (HAL_I2C_Init(&hi2c3) != HAL_OK)
  {
    Error_Handler();
  }

  /** Configure Analogue filter
  */
  if (HAL_I2CEx_ConfigAnalogFilter(&hi2c3, I2C_ANALOGFILTER_ENABLE) != HAL_OK)
  {
    Error_Handler();
  }

  /** Configure Digital filter
  */
  if (HAL_I2CEx_ConfigDigitalFilter(&hi2c3, 0) != HAL_OK)
  {
    Error_Handler();
  }

  /** I2C Fast mode Plus enable
  */
  HAL_I2CEx_EnableFastModePlus(I2C_FASTMODEPLUS_I2C3);

}

static void MX_I2C4_Init(void)
{

  hi2c4.Instance = I2C4;
  hi2c4.Init.Timing = 0x4052060F;
  hi2c4.Init.OwnAddress1 = 0;
  hi2c4.Init.AddressingMode = I2C_ADDRESSINGMODE_7BIT;
  hi2c4.Init.DualAddressMode = I2C_DUALADDRESS_DISABLE;
  hi2c4.Init.OwnAddress2 = 0;
  hi2c4.Init.OwnAddress2Masks = I2C_OA2_NOMASK;
  hi2c4.Init.GeneralCallMode = I2C_GENERALCALL_DISABLE;
  hi2c4.Init.NoStretchMode = I2C_NOSTRETCH_DISABLE;
  if (HAL_I2C_Init(&hi2c4) != HAL_OK)
  {
    Error_Handler();
  }

  /** Configure Analogue filter
  */
  if (HAL_I2CEx_ConfigAnalogFilter(&hi2c4, I2C_ANALOGFILTER_ENABLE) != HAL_OK)
  {
    Error_Handler();
  }

  /** Configure Digital filter
  */
  if (HAL_I2CEx_ConfigDigitalFilter(&hi2c4, 0) != HAL_OK)
  {
    Error_Handler();
  }

  /** I2C Fast mode Plus enable
  */
  HAL_I2CEx_EnableFastModePlus(I2C_FASTMODEPLUS_I2C4);

}

static void MX_OPAMP3_Init(void)
{

  hopamp3.Instance = OPAMP3;
  hopamp3.Init.PowerMode = OPAMP_POWERMODE_NORMALSPEED;
  hopamp3.Init.Mode = OPAMP_FOLLOWER_MODE;
  hopamp3.Init.NonInvertingInput = OPAMP_NONINVERTINGINPUT_DAC;
  hopamp3.Init.InternalOutput = DISABLE;
  hopamp3.Init.TimerControlledMuxmode = OPAMP_TIMERCONTROLLEDMUXMODE_DISABLE;
  hopamp3.Init.UserTrimming = OPAMP_TRIMMING_FACTORY;
  if (HAL_OPAMP_Init(&hopamp3) != HAL_OK)
  {
    Error_Handler();
  }

}

static void MX_OPAMP4_Init(void)
{

  hopamp4.Instance = OPAMP4;
  hopamp4.Init.PowerMode = OPAMP_POWERMODE_NORMALSPEED;
  hopamp4.Init.Mode = OPAMP_FOLLOWER_MODE;
  hopamp4.Init.NonInvertingInput = OPAMP_NONINVERTINGINPUT_DAC;
  hopamp4.Init.InternalOutput = DISABLE;
  hopamp4.Init.TimerControlledMuxmode = OPAMP_TIMERCONTROLLEDMUXMODE_DISABLE;
  hopamp4.Init.UserTrimming = OPAMP_TRIMMING_FACTORY;
  if (HAL_OPAMP_Init(&hopamp4) != HAL_OK)
  {
    Error_Handler();
  }

}

static void MX_OPAMP6_Init(void)
{

  hopamp6.Instance = OPAMP6;
  hopamp6.Init.PowerMode = OPAMP_POWERMODE_NORMALSPEED;
  hopamp6.Init.Mode = OPAMP_FOLLOWER_MODE;
  hopamp6.Init.NonInvertingInput = OPAMP_NONINVERTINGINPUT_DAC;
  hopamp6.Init.InternalOutput = DISABLE;
  hopamp6.Init.TimerControlledMuxmode = OPAMP_TIMERCONTROLLEDMUXMODE_DISABLE;
  hopamp6.Init.UserTrimming = OPAMP_TRIMMING_FACTORY;
  if (HAL_OPAMP_Init(&hopamp6) != HAL_OK)
  {
    Error_Handler();
  }

}

static void MX_SPI1_Init(void)
{

  /* SPI1 parameter configuration*/
  hspi1.Instance = SPI1;
  hspi1.Init.Mode = SPI_MODE_SLAVE;
  hspi1.Init.Direction = SPI_DIRECTION_2LINES;
  hspi1.Init.DataSize = SPI_DATASIZE_4BIT;
  hspi1.Init.CLKPolarity = SPI_POLARITY_LOW;
  hspi1.Init.CLKPhase = SPI_PHASE_1EDGE;
  hspi1.Init.NSS = SPI_NSS_SOFT;
  hspi1.Init.FirstBit = SPI_FIRSTBIT_MSB;
  hspi1.Init.TIMode = SPI_TIMODE_DISABLE;
  hspi1.Init.CRCCalculation = SPI_CRCCALCULATION_DISABLE;
  hspi1.Init.CRCPolynomial = 7;
  hspi1.Init.CRCLength = SPI_CRC_LENGTH_DATASIZE;
  hspi1.Init.NSSPMode = SPI_NSS_PULSE_DISABLE;
  if (HAL_SPI_Init(&hspi1) != HAL_OK)
  {
    Error_Handler();
  }

}

static void MX_SPI2_Init(void)
{

  /* SPI2 parameter configuration*/
  hspi2.Instance = SPI2;
  hspi2.Init.Mode = SPI_MODE_MASTER;
  hspi2.Init.Direction = SPI_DIRECTION_2LINES;
  hspi2.Init.DataSize = SPI_DATASIZE_8BIT;
  hspi2.Init.CLKPolarity = SPI_POLARITY_LOW;
  hspi2.Init.CLKPhase = SPI_PHASE_2EDGE;
  hspi2.Init.NSS = SPI_NSS_SOFT;
  hspi2.Init.BaudRatePrescaler = SPI_BAUDRATEPRESCALER_64;
  hspi2.Init.FirstBit = SPI_FIRSTBIT_MSB;
  hspi2.Init.TIMode = SPI_TIMODE_DISABLE;
  hspi2.Init.CRCCalculation = SPI_CRCCALCULATION_DISABLE;
  hspi2.Init.CRCPolynomial = 7;
  hspi2.Init.CRCLength = SPI_CRC_LENGTH_DATASIZE;
  hspi2.Init.NSSPMode = SPI_NSS_PULSE_DISABLE;
  if (HAL_SPI_Init(&hspi2) != HAL_OK)
  {
    Error_Handler();
  }

}

static void MX_TIM1_Init(void)
{

  TIM_MasterConfigTypeDef sMasterConfig = {0};
  TIM_OC_InitTypeDef sConfigOC = {0};
  TIM_BreakDeadTimeConfigTypeDef sBreakDeadTimeConfig = {0};

  htim1.Instance = TIM1;
  htim1.Init.Prescaler = 0;
  htim1.Init.CounterMode = TIM_COUNTERMODE_UP;
  htim1.Init.Period = 6799;
  htim1.Init.ClockDivision = TIM_CLOCKDIVISION_DIV1;
  htim1.Init.RepetitionCounter = 0;
  htim1.Init.AutoReloadPreload = TIM_AUTORELOAD_PRELOAD_DISABLE;
  if (HAL_TIM_PWM_Init(&htim1) != HAL_OK)
  {
    Error_Handler();
  }
  sMasterConfig.MasterOutputTrigger = TIM_TRGO_RESET;
  sMasterConfig.MasterOutputTrigger2 = TIM_TRGO2_RESET;
  sMasterConfig.MasterSlaveMode = TIM_MASTERSLAVEMODE_DISABLE;
  if (HAL_TIMEx_MasterConfigSynchronization(&htim1, &sMasterConfig) != HAL_OK)
  {
    Error_Handler();
  }
  sConfigOC.OCMode = TIM_OCMODE_PWM1;
  sConfigOC.Pulse = 0;
  sConfigOC.OCPolarity = TIM_OCPOLARITY_HIGH;
  sConfigOC.OCNPolarity = TIM_OCNPOLARITY_HIGH;
  sConfigOC.OCFastMode = TIM_OCFAST_DISABLE;
  sConfigOC.OCIdleState = TIM_OCIDLESTATE_RESET;
  sConfigOC.OCNIdleState = TIM_OCNIDLESTATE_RESET;
  if (HAL_TIM_PWM_ConfigChannel(&htim1, &sConfigOC, TIM_CHANNEL_2) != HAL_OK)
  {
    Error_Handler();
  }
  if (HAL_TIM_PWM_ConfigChannel(&htim1, &sConfigOC, TIM_CHANNEL_3) != HAL_OK)
  {
    Error_Handler();
  }
  sBreakDeadTimeConfig.OffStateRunMode = TIM_OSSR_DISABLE;
  sBreakDeadTimeConfig.OffStateIDLEMode = TIM_OSSI_DISABLE;
  sBreakDeadTimeConfig.LockLevel = TIM_LOCKLEVEL_OFF;
  sBreakDeadTimeConfig.DeadTime = 0;
  sBreakDeadTimeConfig.BreakState = TIM_BREAK_DISABLE;
  sBreakDeadTimeConfig.BreakPolarity = TIM_BREAKPOLARITY_HIGH;
  sBreakDeadTimeConfig.BreakFilter = 0;
  sBreakDeadTimeConfig.BreakAFMode = TIM_BREAK_AFMODE_INPUT;
  sBreakDeadTimeConfig.Break2State = TIM_BREAK2_DISABLE;
  sBreakDeadTimeConfig.Break2Polarity = TIM_BREAK2POLARITY_HIGH;
  sBreakDeadTimeConfig.Break2Filter = 0;
  sBreakDeadTimeConfig.Break2AFMode = TIM_BREAK_AFMODE_INPUT;
  sBreakDeadTimeConfig.AutomaticOutput = TIM_AUTOMATICOUTPUT_DISABLE;
  if (HAL_TIMEx_ConfigBreakDeadTime(&htim1, &sBreakDeadTimeConfig) != HAL_OK)
  {
    Error_Handler();
  }
  HAL_TIM_MspPostInit(&htim1);

}

static void MX_TIM2_Init(void)
{

  TIM_ClockConfigTypeDef sClockSourceConfig = {0};
  TIM_MasterConfigTypeDef sMasterConfig = {0};
  TIM_OC_InitTypeDef sConfigOC = {0};

  htim2.Instance = TIM2;
  htim2.Init.Prescaler = 0;
  htim2.Init.CounterMode = TIM_COUNTERMODE_UP;
  htim2.Init.Period = 6799;
  htim2.Init.ClockDivision = TIM_CLOCKDIVISION_DIV1;
  htim2.Init.AutoReloadPreload = TIM_AUTORELOAD_PRELOAD_DISABLE;
  if (HAL_TIM_Base_Init(&htim2) != HAL_OK)
  {
    Error_Handler();
  }
  sClockSourceConfig.ClockSource = TIM_CLOCKSOURCE_INTERNAL;
  if (HAL_TIM_ConfigClockSource(&htim2, &sClockSourceConfig) != HAL_OK)
  {
    Error_Handler();
  }
  if (HAL_TIM_PWM_Init(&htim2) != HAL_OK)
  {
    Error_Handler();
  }
  sMasterConfig.MasterOutputTrigger = TIM_TRGO_RESET;
  sMasterConfig.MasterSlaveMode = TIM_MASTERSLAVEMODE_DISABLE;
  if (HAL_TIMEx_MasterConfigSynchronization(&htim2, &sMasterConfig) != HAL_OK)
  {
    Error_Handler();
  }
  sConfigOC.OCMode = TIM_OCMODE_PWM1;
  sConfigOC.Pulse = 0;
  sConfigOC.OCPolarity = TIM_OCPOLARITY_HIGH;
  sConfigOC.OCFastMode = TIM_OCFAST_DISABLE;
  if (HAL_TIM_PWM_ConfigChannel(&htim2, &sConfigOC, TIM_CHANNEL_1) != HAL_OK)
  {
    Error_Handler();
  }
  if (HAL_TIM_PWM_ConfigChannel(&htim2, &sConfigOC, TIM_CHANNEL_2) != HAL_OK)
  {
    Error_Handler();
  }
  if (HAL_TIM_PWM_ConfigChannel(&htim2, &sConfigOC, TIM_CHANNEL_3) != HAL_OK)
  {
    Error_Handler();
  }
  if (HAL_TIM_PWM_ConfigChannel(&htim2, &sConfigOC, TIM_CHANNEL_4) != HAL_OK)
  {
    Error_Handler();
  }
  HAL_TIM_MspPostInit(&htim2);

}

static void MX_TIM3_Init(void)
{

  TIM_ClockConfigTypeDef sClockSourceConfig = {0};
  TIM_MasterConfigTypeDef sMasterConfig = {0};
  TIM_OC_InitTypeDef sConfigOC = {0};

  htim3.Instance = TIM3;
  htim3.Init.Prescaler = 0;
  htim3.Init.CounterMode = TIM_COUNTERMODE_UP;
  htim3.Init.Period = 6799;
  htim3.Init.ClockDivision = TIM_CLOCKDIVISION_DIV1;
  htim3.Init.AutoReloadPreload = TIM_AUTORELOAD_PRELOAD_DISABLE;
  if (HAL_TIM_Base_Init(&htim3) != HAL_OK)
  {
    Error_Handler();
  }
  sClockSourceConfig.ClockSource = TIM_CLOCKSOURCE_INTERNAL;
  if (HAL_TIM_ConfigClockSource(&htim3, &sClockSourceConfig) != HAL_OK)
  {
    Error_Handler();
  }
  if (HAL_TIM_PWM_Init(&htim3) != HAL_OK)
  {
    Error_Handler();
  }
  sMasterConfig.MasterOutputTrigger = TIM_TRGO_RESET;
  sMasterConfig.MasterSlaveMode = TIM_MASTERSLAVEMODE_DISABLE;
  if (HAL_TIMEx_MasterConfigSynchronization(&htim3, &sMasterConfig) != HAL_OK)
  {
    Error_Handler();
  }
  sConfigOC.OCMode = TIM_OCMODE_PWM1;
  sConfigOC.Pulse = 0;
  sConfigOC.OCPolarity = TIM_OCPOLARITY_HIGH;
  sConfigOC.OCFastMode = TIM_OCFAST_DISABLE;
  if (HAL_TIM_PWM_ConfigChannel(&htim3, &sConfigOC, TIM_CHANNEL_1) != HAL_OK)
  {
    Error_Handler();
  }
  if (HAL_TIM_PWM_ConfigChannel(&htim3, &sConfigOC, TIM_CHANNEL_2) != HAL_OK)
  {
    Error_Handler();
  }
  if (HAL_TIM_PWM_ConfigChannel(&htim3, &sConfigOC, TIM_CHANNEL_3) != HAL_OK)
  {
    Error_Handler();
  }
  if (HAL_TIM_PWM_ConfigChannel(&htim3, &sConfigOC, TIM_CHANNEL_4) != HAL_OK)
  {
    Error_Handler();
  }
  HAL_TIM_MspPostInit(&htim3);

}

static void MX_TIM4_Init(void)
{

  TIM_ClockConfigTypeDef sClockSourceConfig = {0};
  TIM_MasterConfigTypeDef sMasterConfig = {0};

  htim4.Instance = TIM4;
  htim4.Init.Prescaler = 169;
  htim4.Init.CounterMode = TIM_COUNTERMODE_UP;
  htim4.Init.Period = 666;
  htim4.Init.ClockDivision = TIM_CLOCKDIVISION_DIV1;
  htim4.Init.AutoReloadPreload = TIM_AUTORELOAD_PRELOAD_DISABLE;
  if (HAL_TIM_Base_Init(&htim4) != HAL_OK)
  {
    Error_Handler();
  }
  sClockSourceConfig.ClockSource = TIM_CLOCKSOURCE_INTERNAL;
  if (HAL_TIM_ConfigClockSource(&htim4, &sClockSourceConfig) != HAL_OK)
  {
    Error_Handler();
  }
  sMasterConfig.MasterOutputTrigger = TIM_TRGO_RESET;
  sMasterConfig.MasterSlaveMode = TIM_MASTERSLAVEMODE_DISABLE;
  if (HAL_TIMEx_MasterConfigSynchronization(&htim4, &sMasterConfig) != HAL_OK)
  {
    Error_Handler();
  }

}

static void MX_TIM5_Init(void)
{

  TIM_ClockConfigTypeDef sClockSourceConfig = {0};
  TIM_MasterConfigTypeDef sMasterConfig = {0};

  htim5.Instance = TIM5;
  htim5.Init.Prescaler = 169;
  htim5.Init.CounterMode = TIM_COUNTERMODE_UP;
  htim5.Init.Period = 8332;
  htim5.Init.ClockDivision = TIM_CLOCKDIVISION_DIV1;
  htim5.Init.AutoReloadPreload = TIM_AUTORELOAD_PRELOAD_DISABLE;
  if (HAL_TIM_Base_Init(&htim5) != HAL_OK)
  {
    Error_Handler();
  }
  sClockSourceConfig.ClockSource = TIM_CLOCKSOURCE_INTERNAL;
  if (HAL_TIM_ConfigClockSource(&htim5, &sClockSourceConfig) != HAL_OK)
  {
    Error_Handler();
  }
  sMasterConfig.MasterOutputTrigger = TIM_TRGO_RESET;
  sMasterConfig.MasterSlaveMode = TIM_MASTERSLAVEMODE_DISABLE;
  if (HAL_TIMEx_MasterConfigSynchronization(&htim5, &sMasterConfig) != HAL_OK)
  {
    Error_Handler();
  }

}

static void MX_USART2_UART_Init(void)
{

  huart2.Instance = USART2;
  huart2.Init.BaudRate = 921600;
  huart2.Init.WordLength = UART_WORDLENGTH_8B;
  huart2.Init.StopBits = UART_STOPBITS_1;
  huart2.Init.Parity = UART_PARITY_NONE;
  huart2.Init.Mode = UART_MODE_TX_RX;
  huart2.Init.HwFlowCtl = UART_HWCONTROL_NONE;
  huart2.Init.OverSampling = UART_OVERSAMPLING_16;
  huart2.Init.OneBitSampling = UART_ONE_BIT_SAMPLE_DISABLE;
  huart2.Init.ClockPrescaler = UART_PRESCALER_DIV1;
  huart2.AdvancedInit.AdvFeatureInit = UART_ADVFEATURE_NO_INIT;
  if (HAL_UART_Init(&huart2) != HAL_OK)
  {
    Error_Handler();
  }
  if (HAL_UARTEx_SetTxFifoThreshold(&huart2, UART_TXFIFO_THRESHOLD_1_8) != HAL_OK)
  {
    Error_Handler();
  }
  if (HAL_UARTEx_SetRxFifoThreshold(&huart2, UART_RXFIFO_THRESHOLD_1_8) != HAL_OK)
  {
    Error_Handler();
  }
  if (HAL_UARTEx_DisableFifoMode(&huart2) != HAL_OK)
  {
    Error_Handler();
  }

}

static void MX_DMA_Init(void)
{

  /* DMA controller clock enable */
  __HAL_RCC_DMAMUX1_CLK_ENABLE();
  __HAL_RCC_DMA1_CLK_ENABLE();

  /* DMA interrupt init */
  /* DMA1_Channel1_IRQn interrupt configuration */
  HAL_NVIC_SetPriority(DMA1_Channel1_IRQn, 5, 0);
  HAL_NVIC_EnableIRQ(DMA1_Channel1_IRQn);

}

/* FMC initialization function */
static void MX_FMC_Init(void)
{

  FMC_NORSRAM_TimingTypeDef Timing = {0};

  /** Perform the SRAM1 memory initialization sequence
  */
  hsram1.Instance = FMC_NORSRAM_DEVICE;
  hsram1.Extended = FMC_NORSRAM_EXTENDED_DEVICE;
  /* hsram1.Init */
  hsram1.Init.NSBank = FMC_NORSRAM_BANK1;
  hsram1.Init.DataAddressMux = FMC_DATA_ADDRESS_MUX_DISABLE;
  hsram1.Init.MemoryType = FMC_MEMORY_TYPE_SRAM;
  hsram1.Init.MemoryDataWidth = FMC_NORSRAM_MEM_BUS_WIDTH_8;
  hsram1.Init.BurstAccessMode = FMC_BURST_ACCESS_MODE_DISABLE;
  hsram1.Init.WaitSignalPolarity = FMC_WAIT_SIGNAL_POLARITY_LOW;
  hsram1.Init.WaitSignalActive = FMC_WAIT_TIMING_BEFORE_WS;
  hsram1.Init.WriteOperation = FMC_WRITE_OPERATION_ENABLE;
  hsram1.Init.WaitSignal = FMC_WAIT_SIGNAL_DISABLE;
  hsram1.Init.ExtendedMode = FMC_EXTENDED_MODE_DISABLE;
  hsram1.Init.AsynchronousWait = FMC_ASYNCHRONOUS_WAIT_DISABLE;
  hsram1.Init.WriteBurst = FMC_WRITE_BURST_DISABLE;
  hsram1.Init.ContinuousClock = FMC_CONTINUOUS_CLOCK_SYNC_ONLY;
  hsram1.Init.WriteFifo = FMC_WRITE_FIFO_DISABLE;
  hsram1.Init.NBLSetupTime = 0;
  hsram1.Init.PageSize = FMC_PAGE_SIZE_NONE;
  hsram1.Init.MaxChipSelectPulse = DISABLE;
  /* Timing */
  Timing.AddressSetupTime = 1;
  Timing.AddressHoldTime = 15;
  Timing.DataSetupTime = 4;
  Timing.DataHoldTime = 1;
  Timing.BusTurnAroundDuration = 0;
  Timing.CLKDivision = 16;
  Timing.DataLatency = 17;
  Timing.AccessMode = FMC_ACCESS_MODE_A;
  /* ExtTiming */

  if (HAL_SRAM_Init(&hsram1, &Timing, NULL) != HAL_OK)
  {
    Error_Handler( );
  }

}

static void MX_GPIO_Init(void)
{
  GPIO_InitTypeDef GPIO_InitStruct = {0};

  /* GPIO Ports Clock Enable */
  __HAL_RCC_GPIOE_CLK_ENABLE();
  __HAL_RCC_GPIOC_CLK_ENABLE();
  __HAL_RCC_GPIOF_CLK_ENABLE();
  __HAL_RCC_GPIOA_CLK_ENABLE();
  __HAL_RCC_GPIOB_CLK_ENABLE();
  __HAL_RCC_GPIOD_CLK_ENABLE();

  /*Configure GPIO pin Output Level */
  HAL_GPIO_WritePin(GPIOC, DISP_RST_Pin|SHIFTREG_LAT_Pin|LDAC4_Pin|LDAC3_Pin|LDAC2_Pin, GPIO_PIN_RESET);

  /*Configure GPIO pin Output Level */
  HAL_GPIO_WritePin(SHIFTREG_OE_GPIO_Port, SHIFTREG_OE_Pin, GPIO_PIN_SET);

  /*Configure GPIO pin Output Level */
  HAL_GPIO_WritePin(LED_TEST_GPIO_Port, LED_TEST_Pin, GPIO_PIN_RESET);

  /*Configure GPIO pin Output Level */
  HAL_GPIO_WritePin(GPIOA, SHIFTREG_Clock_Pin|SHIFTREG_Data_Pin, GPIO_PIN_RESET);

  /*Configure GPIO pin Output Level */
  HAL_GPIO_WritePin(GPIOE, DISP_CS3_Pin|DISP_CS2_Pin|DISP_CS1_Pin|DISP_CS0_Pin, GPIO_PIN_RESET);

  /*Configure GPIO pin Output Level */
  HAL_GPIO_WritePin(LED_Latch_GPIO_Port, LED_Latch_Pin, GPIO_PIN_RESET);

  /*Configure GPIO pin Output Level */
  HAL_GPIO_WritePin(GPIOD, LDAC0_Pin|LDAC1_Pin, GPIO_PIN_RESET);

  /*Configure GPIO pins : F3_TOUCH_Pin F2_TOUCH_Pin F0_TOUCH_Pin */
  GPIO_InitStruct.Pin = F3_TOUCH_Pin|F2_TOUCH_Pin|F0_TOUCH_Pin;
  GPIO_InitStruct.Mode = GPIO_MODE_INPUT;
  GPIO_InitStruct.Pull = GPIO_NOPULL;
  HAL_GPIO_Init(GPIOE, &GPIO_InitStruct);

  /*Configure GPIO pins : DISP_RST_Pin SHIFTREG_LAT_Pin LDAC4_Pin LDAC3_Pin
                           LDAC2_Pin */
  GPIO_InitStruct.Pin = DISP_RST_Pin|SHIFTREG_LAT_Pin|LDAC4_Pin|LDAC3_Pin
                          |LDAC2_Pin;
  GPIO_InitStruct.Mode = GPIO_MODE_OUTPUT_PP;
  GPIO_InitStruct.Pull = GPIO_NOPULL;
  GPIO_InitStruct.Speed = GPIO_SPEED_FREQ_LOW;
  HAL_GPIO_Init(GPIOC, &GPIO_InitStruct);

  /*Configure GPIO pins : SHIFTREG_OE_Pin LED_TEST_Pin */
  GPIO_InitStruct.Pin = SHIFTREG_OE_Pin|LED_TEST_Pin;
  GPIO_InitStruct.Mode = GPIO_MODE_OUTPUT_PP;
  GPIO_InitStruct.Pull = GPIO_NOPULL;
  GPIO_InitStruct.Speed = GPIO_SPEED_FREQ_LOW;
  HAL_GPIO_Init(GPIOF, &GPIO_InitStruct);

  /*Configure GPIO pins : SHIFTREG_Clock_Pin SHIFTREG_Data_Pin */
  GPIO_InitStruct.Pin = SHIFTREG_Clock_Pin|SHIFTREG_Data_Pin;
  GPIO_InitStruct.Mode = GPIO_MODE_OUTPUT_PP;
  GPIO_InitStruct.Pull = GPIO_NOPULL;
  GPIO_InitStruct.Speed = GPIO_SPEED_FREQ_LOW;
  HAL_GPIO_Init(GPIOA, &GPIO_InitStruct);

  /*Configure GPIO pins : F1_TOUCH_Pin SPI1_CS_IN_Pin */
  GPIO_InitStruct.Pin = F1_TOUCH_Pin|SPI1_CS_IN_Pin;
  GPIO_InitStruct.Mode = GPIO_MODE_INPUT;
  GPIO_InitStruct.Pull = GPIO_NOPULL;
  HAL_GPIO_Init(GPIOB, &GPIO_InitStruct);

  /*Configure GPIO pins : DISP_CS3_Pin DISP_CS2_Pin DISP_CS1_Pin DISP_CS0_Pin */
  GPIO_InitStruct.Pin = DISP_CS3_Pin|DISP_CS2_Pin|DISP_CS1_Pin|DISP_CS0_Pin;
  GPIO_InitStruct.Mode = GPIO_MODE_OUTPUT_PP;
  GPIO_InitStruct.Pull = GPIO_NOPULL;
  GPIO_InitStruct.Speed = GPIO_SPEED_FREQ_LOW;
  HAL_GPIO_Init(GPIOE, &GPIO_InitStruct);

  /*Configure GPIO pin : LED_Latch_Pin */
  GPIO_InitStruct.Pin = LED_Latch_Pin;
  GPIO_InitStruct.Mode = GPIO_MODE_OUTPUT_PP;
  GPIO_InitStruct.Pull = GPIO_NOPULL;
  GPIO_InitStruct.Speed = GPIO_SPEED_FREQ_LOW;
  HAL_GPIO_Init(LED_Latch_GPIO_Port, &GPIO_InitStruct);

  /*Configure GPIO pins : LDAC0_Pin LDAC1_Pin */
  GPIO_InitStruct.Pin = LDAC0_Pin|LDAC1_Pin;
  GPIO_InitStruct.Mode = GPIO_MODE_OUTPUT_PP;
  GPIO_InitStruct.Pull = GPIO_NOPULL;
  GPIO_InitStruct.Speed = GPIO_SPEED_FREQ_LOW;
  HAL_GPIO_Init(GPIOD, &GPIO_InitStruct);

}

void StartDefaultTask(void *argument)
{
  /* USER CODE BEGIN 5 */
  // displays_test_pattern(); // the channel display task draws the screens now

  //led_loading(true);

  for (;;) // this MUST STAY
  {
    vTaskDelay(portMAX_DELAY);
  }

  /* USER CODE END 5 */
}

void HAL_TIM_PeriodElapsedCallback(TIM_HandleTypeDef *htim)
{
  if (htim->Instance == TIM7)
  {
    HAL_IncTick();
  }
  /* USER CODE BEGIN Callback 1 */

  // I2C Scheduler
  else if (htim->Instance == TIM4){
    i2c_scheduler_trigger_frame();
    fader_poller_trigger_frame();
  }

  // skylar (adding the ISR for LED handler)
  else if (htim->Instance == TIM5)
  {
    led_handler_notify_from_isr();
  }

  /* USER CODE END Callback 1 */
}

void Error_Handler(void)
{
  /* USER CODE BEGIN Error_Handler_Debug */
  printf("\r\nError!!!!!!!!!!\n");
  __disable_irq();
  while (1)
  {
  }
  /* USER CODE END Error_Handler_Debug */
}
